# M460 register map
File version: 1.0
Registers are 32-bit, read-write, reset 0x0 unless marked. A register's access mark holds for its fields unless they carry their own. Offsets are from the block's base; [hi:lo] are bit positions; {n}, {i} and the like mark numbered series.

## GPIOD — GPIO Register Map
Base 0x400040C0
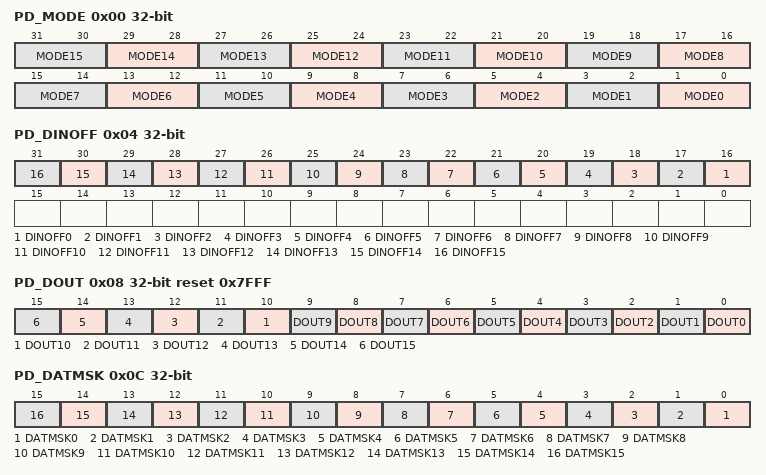
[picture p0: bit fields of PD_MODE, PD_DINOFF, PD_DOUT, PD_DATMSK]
0x00 PD_MODE reset not defined — PD I/O Mode Control
  [all] fields
    0=Px.n is in Input mode; 1=Px.n is in Push-pull Output mode; 2=Px.n is in Open-drain Output mode; 3=Px.n is in Quasi-bidirectional mode
  [2n+1:2n] MODE{n} (n=0..15) — Port A-J I/O Pin[n] Mode Control. Determine each I/O mode of Px.n pins.
0x04 PD_DINOFF — PD Digital Input Path Disable Control
  [all] fields
    0=Px.n digital input path Enabled; 1=Px.n digital input path Disabled (digital input tied to low)
  [n+16] DINOFF{n} (n=0..15) — Port A-J Pin[n] Digital Input Path Disable Bit. Each of these bits is used to control if the digital input path of corresponding Px.n pin is disabled. If input is analog signal, users can disable Px.n digital input path to avoid input current leakage.
0x08 PD_DOUT reset 0x7FFF — PD Data Output Value
  [all] fields
    0=Px.n will drive Low if the Px.n pin is configured as Push-pull output, Open-drain output or Quasi-bidirectional mode; 1=Px.n will drive High if the Px.n pin is configured as Push-pull output or Quasi-bidirectional mode
  [n] DOUT{n} (n=0..15) — Port A-J Pin[n] Output Value. Each of these bits controls the status of a Px.n pin when the Px.n is configured as Push-pull output, Open-drain output or Quasi-bidirectional mode.
0x0C PD_DATMSK — PD Data Output Write Mask
  [all] fields
    0=Corresponding DOUT (Px_DOUT[n]) bit can be updated; 1=Corresponding DOUT (Px_DOUT[n]) bit protected
  [n] DATMSK{n} (n=0..15) — Port A-J Pin[n] Data Output Write Mask. These bits are used to protect the corresponding DOUT (Px_DOUT[n]) bit. When the DATMSK (Px_DATMSK[n]) bit is set to 1, the corresponding DOUT (Px_DOUT[n]) bit is protected. If the write signal is masked, writing data to the protect bit is ignored.
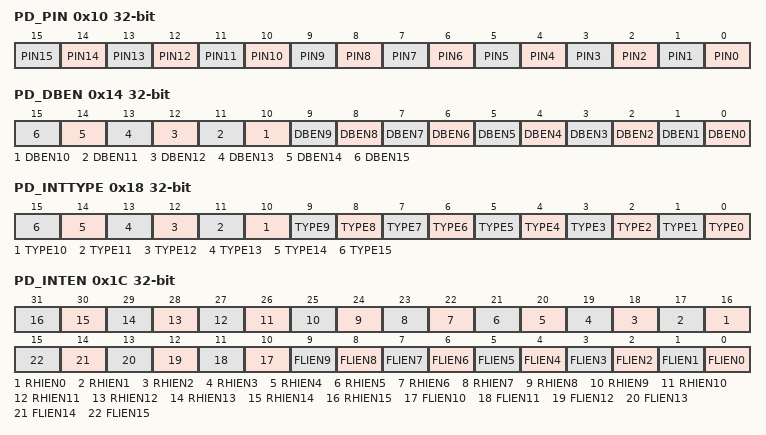
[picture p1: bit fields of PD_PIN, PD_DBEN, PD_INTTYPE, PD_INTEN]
0x10 PD_PIN ro (reset mask 0xFFFF0000) — PD Pin Value
  [n] PIN{n} (n=0..15) — Port A-J Pin[n] Pin Value. Each bit of the register reflects the actual status of the respective Px.n pin. If the bit is 1, it indicates the corresponding pin status is high; else the pin status is low. Note:
0x14 PD_DBEN — PD De-bounce Enable Control Register
  [all] fields
    0=Px.n de-bounce function Disabled; 1=Px.n de-bounce function Enabled
  [n] DBEN{n} (n=0..15) — Port A-J Pin[n] Input Signal De-bounce Enable Bit. The DBEN[n] bit is used to enable the de-bounce function for each corresponding bit. If the input signal pulse width cannot be sampled by continuous two de-bounce sample cycle, the input signal transition is seen as the signal bounce and will not trigger the interrupt. The de-bounce clock source is controlled by DBCLKSRC (Px_DBCTL [4]), one de-bounce sample cycle period is controlled by DBCLKSEL (Px_DBCTL [3:0]).
0x18 PD_INTTYPE — PD Interrupt Trigger Type Control
  [all] fields
    0=Edge trigger interrupt; 1=Level trigger interrupt
  [n] TYPE{n} (n=0..15) — Port A-J Pin[n] Edge or Level Detection Interrupt Trigger Type Control. TYPE (Px_INTTYPE[n]) bit is used to control the triggered interrupt is by level trigger or by edge trigger. If the interrupt is by edge trigger, the trigger source can be controlled by de-bounce. If the interrupt is by level trigger, the input source is sampled by one HCLK clock and generates the interrupt.
0x1C PD_INTEN — PD Interrupt Enable Control Register
  [n+16] RHIEN{n} (n=0..15) — Port A-J Pin[n] Rising Edge or High Level Interrupt Trigger Type Enable Bit. The RHIEN (Px_INTEN[n+16]) bit is used to enable the interrupt for each of the corresponding input Px.n pin. Set bit to 1 also enable the pin wake-up function. When setting the RHIEN (Px_INTEN[n+16]) bit to 1 : If the interrupt is level trigger (TYPE (Px_INTTYPE[n]) bit is set to 1), the input Px.n pin will generate the interrupt while this pin state is at high level. If the interrupt is edge trigger (TYPE (Px_INTTYPE[n]) bit is set to 0), the input Px.n pin will generate the interrupt while this pin state changed from low to high.
    0=Px.n level high or low to high interrupt Disabled; 1=Px.n level high or low to high interrupt Enabled
  [n] FLIEN{n} (n=0..15) — Port A-J Pin[n] Falling Edge or Low Level Interrupt Trigger Type Enable Bit. The FLIEN (Px_INTEN[n]) bit is used to enable the interrupt for each of the corresponding input Px.n pin. Set bit to 1 also enable the pin wake-up function. When setting the FLIEN (Px_INTEN[n]) bit to 1: If the interrupt is level trigger (TYPE (Px_INTTYPE[n]) bit is set to 1), the input Px.n pin will generate the interrupt while this pin state is at low level. If the interrupt is edge trigger (TYPE (Px_INTTYPE[n]) bit is set to 0), the input Px.n pin will generate the interrupt while this pin state changed from high to low.
    0=Px.n level low or high to low interrupt Disabled; 1=Px.n level low or high to low interrupt Enabled
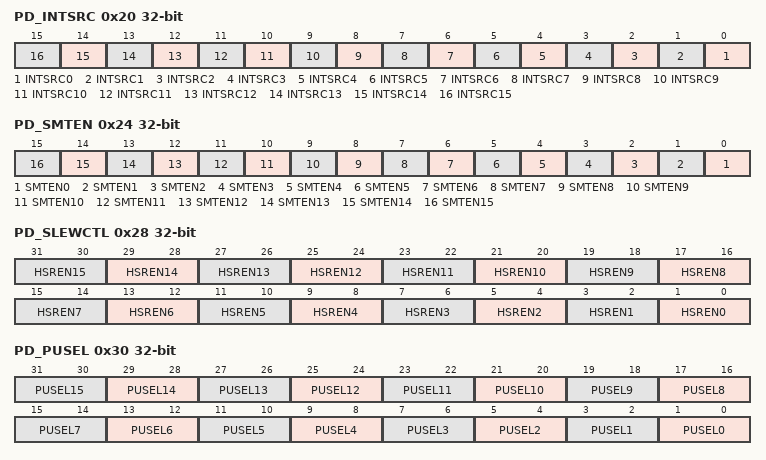
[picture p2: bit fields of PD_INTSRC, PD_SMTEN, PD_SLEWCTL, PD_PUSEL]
0x20 PD_INTSRC (reset mask 0xFFFF0000) — PD Interrupt Source Flag
  [all] fields
    0=No action. No interrupt at Px.n; 1=Clear the corresponding pending interrupt. Px.n generates an interrupt
  [n] INTSRC{n} (n=0..15) — Port A-J Pin[n] Interrupt Source Flag. Write Operation:
0x24 PD_SMTEN — PD Input Schmitt Trigger Enable Register
  [all] fields
    0=Px.n input schmitt trigger function Disabled; 1=Px.n input schmitt trigger function Enabled
  [n] SMTEN{n} (n=0..15) — Port A-J Pin[n] Input Schmitt Trigger Enable Bit
0x28 PD_SLEWCTL — PD High Slew Rate Control Register
  [all] fields
    0=Px.n output with normal slew rate mode; 1=Px.n output with high slew rate mode; 2=Px.n output with fast slew rate mode)
  [2n+1:2n] HSREN{n} (n=0..15) — Port A-J Pin[n] High Slew Rate Control. Note 2: Please refer to the Datasheet for detailed pin operation voltage information about VDD, VDDIO and VBAT electrical characteristics.
0x30 PD_PUSEL — PD Pull-up and Pull-down Selection Register
  [all] fields
    0=Px.n pull-up and pull-down disable; 1=Px.n pull-up enable; 2=Px.n pull-down enable
  [2n+1:2n] PUSEL{n} (n=0..15) — Port A-J Pin[n] Pull-up and Pull-down Enable Register. Determine each I/O Pull-up/pull-down of Px.n pins.
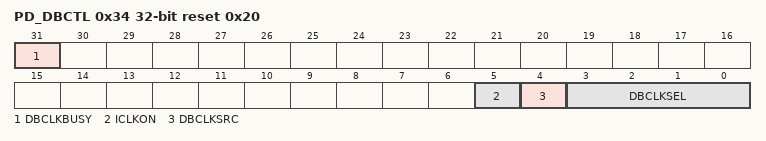
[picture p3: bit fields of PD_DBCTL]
0x34 PD_DBCTL reset 0x20 — PD Interrupt De-bounce Control Register
  [31] DBCLKBUSY ro — De-bounce Clock Switching Busy Flag (Read Only). This bit is set when de-bounce clock source is changed by setting DBCLKSRC(Px_DBCTL[4]). And it is cleared after de-bounce clock source switching is finished. De-bounce function can work normally after de-bounce clock switch done.
    0=De-bounce clock switch done; 1=De-bounce clock is switching
  [5] ICLKON — Interrupt Clock on Mode
    0=Edge detection circuit is active only if I/O pin corresponding RHIEN (Px_INTEN[n+16])/FLIEN (Px_INTEN[n]) bit is set to 1. If corresponding RHIEN or FLIEN is 0, the clock of I/O detect circuit is stopped and interrupt source flag(Px_INTSRC) cannot be clear also; 1=All I/O pins edge detection circuit is always active after reset
  [4] DBCLKSRC — De-bounce Counter Clock Source Selection
    0=De-bounce counter clock source is the HCLK; 1=De-bounce counter clock source is the 10 kHz internal low speed RC oscillator (LIRC)
  [3:0] DBCLKSEL — De-bounce Sampling Cycle Selection
    0=Sample interrupt input once per 1 clocks; 1=Sample interrupt input once per 2 clocks; 2=Sample interrupt input once per 4 clocks; 3=Sample interrupt input once per 8 clocks; 4=Sample interrupt input once per 16 clocks; 5=Sample interrupt input once per 32 clocks; 6=Sample interrupt input once per 64 clocks; 7=Sample interrupt input once per 128 clocks; 8=Sample interrupt input once per 256 clocks; 9=Sample interrupt input once per 2*256 clocks; 10=Sample interrupt input once per 4*256 clocks; 11=Sample interrupt input once per 8*256 clocks; 12=Sample interrupt input once per 16*256 clocks; 13=Sample interrupt input once per 32*256 clocks; 14=Sample interrupt input once per 64*256 clocks; 15=Sample interrupt input once per 128*256 clocks
